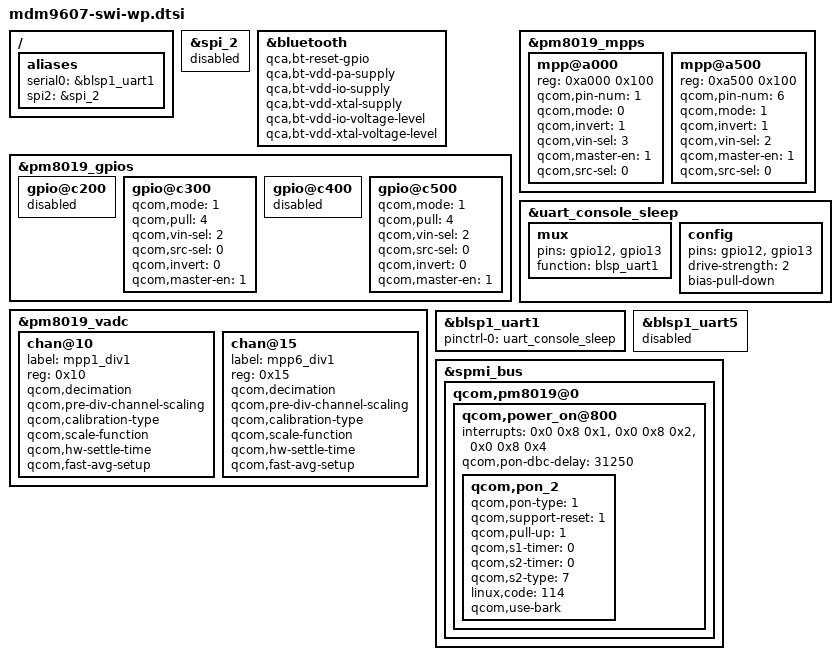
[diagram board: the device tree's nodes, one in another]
/*
 * Copyright (c) 2015-2016, The Linux Foundation. All rights reserved.
 *
 * This program is free software; you can redistribute it and/or modify
 * it under the terms of the GNU General Public License version 2 and
 * only version 2 as published by the Free Software Foundation.
 *
 * This program is distributed in the hope that it will be useful,
 * but WITHOUT ANY WARRANTY; without even the implied warranty of
 * MERCHANTABILITY or FITNESS FOR A PARTICULAR PURPOSE.  See the
 * GNU General Public License for more details.
 */
/*Inherit the ar DTS and overlay the difference */
#include "mdm9607-swi-common.dtsi"

/ {
	aliases {
		serial0 = &blsp1_uart1;
		spi2  = &spi_2;
	};
};

&spi_2 {
	status = "disabled";
};

&bluetooth {
	qca,bt-reset-gpio;
	qca,bt-vdd-pa-supply;
	qca,bt-vdd-io-supply;
	qca,bt-vdd-xtal-supply;
	qca,bt-vdd-io-voltage-level;
	qca,bt-vdd-xtal-voltage-level;
};

&pm8019_gpios {
	gpio@c200 { /* GPIO 3 */
		status = "disabled";
	};

	gpio@c300 { /* GPIO 4 */
		qcom,mode = <1>;         /* Digital output*/
		qcom,pull = <4>;         /* Pulldown 10uA */
		qcom,vin-sel = <2>;      /* VIN2 */
		qcom,src-sel = <0>;      /* GPIO */
		qcom,invert = <0>;       /* Invert */
		qcom,master-en = <1>;    /* Enable GPIO */
		status = "ok";
	};

	gpio@c400 { /* GPIO 5 */
		status = "disabled";
	};

	gpio@c500 { /* GPIO 6 */
		qcom,mode = <1>;         /* Digital output*/
		qcom,pull = <4>;         /* Pulldown 10uA */
		qcom,vin-sel = <2>;      /* VIN2 */
		qcom,src-sel = <0>;      /* GPIO */
		qcom,invert = <0>;       /* Invert */
		qcom,master-en = <1>;    /* Enable GPIO */
		status = "ok";
	};

};

/* WP76 ADC configuration only used MPP2/4, which are already defined in mdm9607-swi-ar.dtsi*/
&pm8019_vadc {
	/* Disable VADC Channel configuration MPP1*/
	chan@10 {
		label = "mpp1_div1";
		reg = <0x10>;
		qcom,decimation;
		qcom,pre-div-channel-scaling;
		qcom,calibration-type;
		qcom,scale-function;
		qcom,hw-settle-time;
		qcom,fast-avg-setup;
	};
	/* Disable VADC Channel configuration MPP6*/
	chan@15 {
		label = "mpp6_div1";
		reg = <0x15>;
		qcom,decimation;
		qcom,pre-div-channel-scaling;
		qcom,calibration-type;
		qcom,scale-function;
		qcom,hw-settle-time;
		qcom,fast-avg-setup;
	};
};

&pm8019_mpps {
	/* MPP1 */
	mpp@a000 {
		reg = <0xa000 0x100>;
		qcom,pin-num = <1>;

		qcom,mode = <0>; /* DIG input */
		qcom,invert = <1>; /* Enable MPP */
		qcom,vin-sel = <3>;
		qcom,master-en = <1>;
		qcom,src-sel = <0>; /* Function constant */
		status = "ok";
	};

	/* MPP6 */
	mpp@a500 {
		reg = <0xa500 0x100>;
		qcom,pin-num = <6>;

		qcom,mode = <1>; /* DIG output */
		qcom,invert = <1>; /* Enable MPP */
		qcom,vin-sel = <2>;
		qcom,master-en = <1>;
		qcom,src-sel = <0>; /* Function constant */
		status = "ok";
	};
};

&uart_console_sleep {
	mux {
		pins = "gpio12", "gpio13";
		function = "blsp_uart1";
	};
	config {
		pins = "gpio12", "gpio13";
		drive-strength = <2>;
		bias-pull-down;
	};
};

&blsp1_uart1 {
	status = "ok";
	pinctrl-names = "default";
	pinctrl-0 = <&uart_console_sleep>;
};

&blsp1_uart5 {
	status = "disabled";
};

&spmi_bus {
	qcom,pm8019@0 {
		qcom,power_on@800 {
			interrupts = <0x0 0x8 0x1>,
			<0x0 0x8 0x2>,
			<0x0 0x8 0x4>;
			interrupt-names = "resin", "cblpwr", "resin-bark";
			qcom,pon-dbc-delay = <31250>;

			qcom,pon_2 {
				qcom,pon-type = <1>; /* resin */
				qcom,support-reset = <1>;
				qcom,pull-up = <1>;
				qcom,s1-timer = <0>; /* s1 default bark irq time, it can be reconfigured by NV */
				qcom,s2-timer = <0>; /* s2 default delay time, it can be reconfigured by NV */
				qcom,s2-type = <7>; /* HARD RESET*/
				linux,code = <114>; /* No reset key value, so use KEY_VOLUMEDOWN like other device */
				qcom,use-bark; /* handle bark irq */
			};
		};
	};
};
